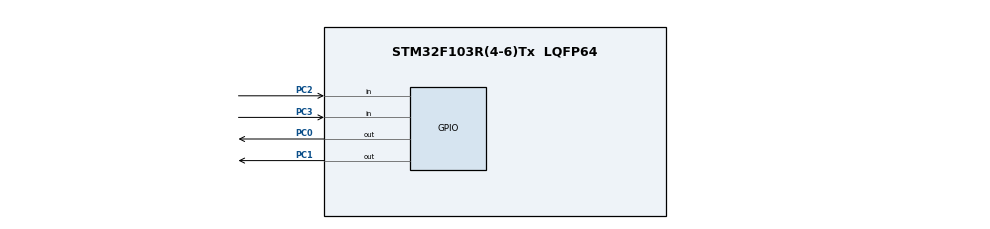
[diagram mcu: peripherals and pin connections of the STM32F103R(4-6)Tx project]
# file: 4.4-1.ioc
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Mcu.Family=STM32F1
Mcu.Name=STM32F103R(4-6)Tx
Mcu.Package=LQFP64
NVIC.PriorityGroup=NVIC_PRIORITYGROUP_4
PC0.PinState=GPIO_PIN_SET
PC0.Signal=GPIO_Output
PC1.PinState=GPIO_PIN_SET
PC1.Signal=GPIO_Output
PC2.Signal=GPIO_Input
PC3.Signal=GPIO_Input
ProjectManager.HeapSize=0x200
ProjectManager.StackSize=0x400
ProjectManager.TargetToolchain=STM32CubeIDE
RCC.APB1Freq_Value=8000000
RCC.APB2Freq_Value=8000000
VP_SYS_VS_ND.Mode=No_Debug
board=custom

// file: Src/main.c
/* USER CODE BEGIN Header */
/**
  ******************************************************************************
  * @file           : main.c
  * @brief          : Main program body
  ******************************************************************************
  * @attention
  *
  * <h2><center>&copy; Copyright (c) 2019 STMicroelectronics.
  * All rights reserved.</center></h2>
  *
  * This software component is licensed by ST under BSD 3-Clause license,
  * the "License"; You may not use this file except in compliance with the
  * License. You may obtain a copy of the License at:
  *                        opensource.org/licenses/BSD-3-Clause
  *
  ******************************************************************************
  */
/* USER CODE END Header */

#include "main.h"

void SystemClock_Config(void);
static void MX_GPIO_Init(void);

int main(void)
{

  /* MCU Configuration--------------------------------------------------------*/

  /* Reset of all peripherals, Initializes the Flash interface and the Systick. */
  HAL_Init();

  /* Configure the system clock */
  SystemClock_Config();

  /* Initialize all configured peripherals */
  MX_GPIO_Init();

  /* Infinite loop */
  /* USER CODE BEGIN WHILE */
  while (1)
  {
	  uint32_t count=0;
	  while(HAL_GPIO_ReadPin(GPIOC, GPIO_PIN_2)==0)
	  {
		  count++;
		  if(count>40)break;
		  HAL_Delay(25);
	  }
	  if(count>1 && count<40)
	  {
		  HAL_GPIO_WritePin(GPIOC, GPIO_PIN_0,0);
	  }
	  else if(count>=40)
	  {
		  HAL_GPIO_WritePin(GPIOC, GPIO_PIN_1,0);
	  }
	  while(count>0 && HAL_GPIO_ReadPin(GPIOC, GPIO_PIN_2)==0);

	  if(HAL_GPIO_ReadPin(GPIOC, GPIO_PIN_3)==0)
	  {
		  HAL_Delay(25);
		  if(HAL_GPIO_ReadPin(GPIOC, GPIO_PIN_3)==0)
		  {
			  HAL_GPIO_WritePin(GPIOC, GPIO_PIN_0|GPIO_PIN_1,1);
		  }
	  }
    /* USER CODE END WHILE */

  }
}

void SystemClock_Config(void)
{
  RCC_OscInitTypeDef RCC_OscInitStruct = {0};
  RCC_ClkInitTypeDef RCC_ClkInitStruct = {0};

  /** Initializes the CPU, AHB and APB busses clocks
  */
  RCC_OscInitStruct.OscillatorType = RCC_OSCILLATORTYPE_HSI;
  RCC_OscInitStruct.HSIState = RCC_HSI_ON;
  RCC_OscInitStruct.HSICalibrationValue = RCC_HSICALIBRATION_DEFAULT;
  RCC_OscInitStruct.PLL.PLLState = RCC_PLL_NONE;
  if (HAL_RCC_OscConfig(&RCC_OscInitStruct) != HAL_OK)
  {
    Error_Handler();
  }
  /** Initializes the CPU, AHB and APB busses clocks
  */
  RCC_ClkInitStruct.ClockType = RCC_CLOCKTYPE_HCLK|RCC_CLOCKTYPE_SYSCLK
                              |RCC_CLOCKTYPE_PCLK1|RCC_CLOCKTYPE_PCLK2;
  RCC_ClkInitStruct.SYSCLKSource = RCC_SYSCLKSOURCE_HSI;
  RCC_ClkInitStruct.AHBCLKDivider = RCC_SYSCLK_DIV1;
  RCC_ClkInitStruct.APB1CLKDivider = RCC_HCLK_DIV1;
  RCC_ClkInitStruct.APB2CLKDivider = RCC_HCLK_DIV1;

  if (HAL_RCC_ClockConfig(&RCC_ClkInitStruct, FLASH_LATENCY_0) != HAL_OK)
  {
    Error_Handler();
  }
}

static void MX_GPIO_Init(void)
{
  GPIO_InitTypeDef GPIO_InitStruct = {0};

  /* GPIO Ports Clock Enable */
  __HAL_RCC_GPIOC_CLK_ENABLE();

  /*Configure GPIO pin Output Level */
  HAL_GPIO_WritePin(GPIOC, GPIO_PIN_0|GPIO_PIN_1, GPIO_PIN_SET);

  /*Configure GPIO pins : PC0 PC1 */
  GPIO_InitStruct.Pin = GPIO_PIN_0|GPIO_PIN_1;
  GPIO_InitStruct.Mode = GPIO_MODE_OUTPUT_PP;
  GPIO_InitStruct.Pull = GPIO_NOPULL;
  GPIO_InitStruct.Speed = GPIO_SPEED_FREQ_LOW;
  HAL_GPIO_Init(GPIOC, &GPIO_InitStruct);

  /*Configure GPIO pins : PC2 PC3 */
  GPIO_InitStruct.Pin = GPIO_PIN_2|GPIO_PIN_3;
  GPIO_InitStruct.Mode = GPIO_MODE_INPUT;
  GPIO_InitStruct.Pull = GPIO_NOPULL;
  HAL_GPIO_Init(GPIOC, &GPIO_InitStruct);

}

void Error_Handler(void)
{
}

/************************ (C) COPYRIGHT STMicroelectronics *****END OF FILE****/
